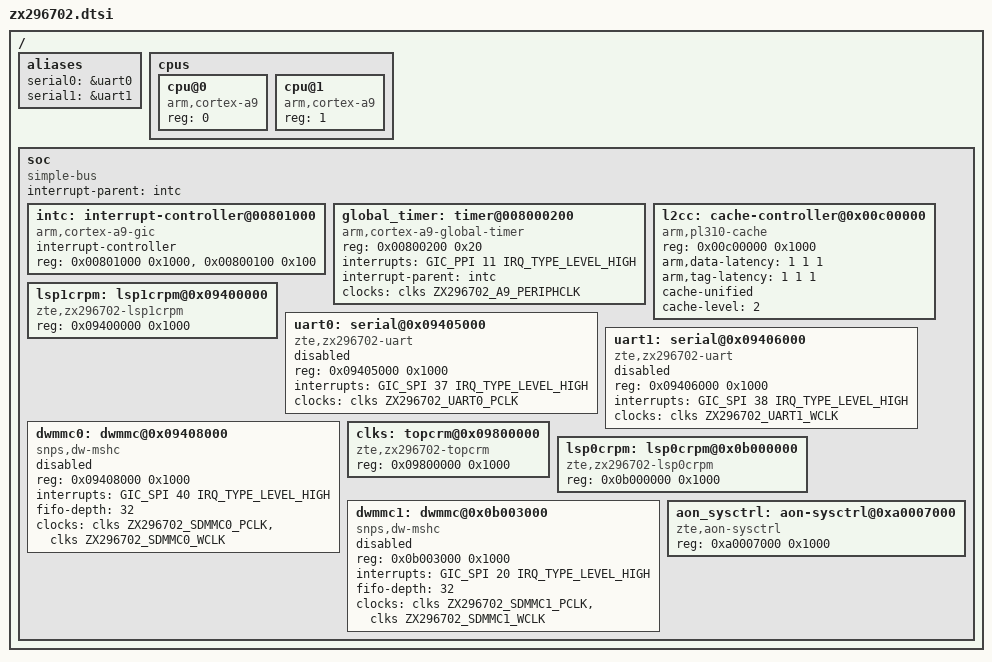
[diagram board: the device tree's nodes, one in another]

#include "skeleton.dtsi"
#include <dt-bindings/clock/zx296702-clock.h>
#include <dt-bindings/interrupt-controller/arm-gic.h>

/ {
	aliases {
		serial0 = &uart0;
		serial1 = &uart1;
	};

	cpus {
		#address-cells = <1>;
		#size-cells = <0>;

		cpu@0 {
			compatible = "arm,cortex-a9";
			device_type = "cpu";
			reg = <0>;
		};

		cpu@1 {
			compatible = "arm,cortex-a9";
			device_type = "cpu";
			reg = <1>;
		};
	};


	soc {
		#address-cells = <1>;
		#size-cells = <1>;
		compatible = "simple-bus";
		interrupt-parent = <&intc>;
		ranges;

		intc: interrupt-controller@00801000 {
			compatible = "arm,cortex-a9-gic";
			#interrupt-cells = <3>;
			#address-cells = <1>;
			#size-cells = <1>;
			interrupt-controller;
			reg = <0x00801000 0x1000>,
			      <0x00800100 0x100>;
		};

		global_timer: timer@008000200 {
			compatible = "arm,cortex-a9-global-timer";
			reg = <0x00800200 0x20>;
			interrupts = <GIC_PPI 11 IRQ_TYPE_LEVEL_HIGH>;
			interrupt-parent = <&intc>;
			clocks = <&clks ZX296702_A9_PERIPHCLK>;
		};

		l2cc: cache-controller@0x00c00000 {
			compatible = "arm,pl310-cache";
			reg = <0x00c00000 0x1000>;
			arm,data-latency = <1 1 1>;
			arm,tag-latency = <1 1 1>;
			cache-unified;
			cache-level = <2>;
		};

		lsp1crpm: lsp1crpm@0x09400000 {
			compatible = "zte,zx296702-lsp1crpm";
			reg = <0x09400000 0x1000>;
		};

		uart0: serial@0x09405000 {
			compatible = "zte,zx296702-uart";
			reg = <0x09405000 0x1000>;
			interrupts = <GIC_SPI 37 IRQ_TYPE_LEVEL_HIGH>;
			clocks = <&clks ZX296702_UART0_PCLK>;
			status = "disabled";
		};

		uart1: serial@0x09406000 {
			compatible = "zte,zx296702-uart";
			reg = <0x09406000 0x1000>;
			interrupts = <GIC_SPI 38 IRQ_TYPE_LEVEL_HIGH>;
			clocks = <&clks ZX296702_UART1_WCLK>;
			status = "disabled";
		};

		dwmmc0: dwmmc@0x09408000 {
			compatible = "snps,dw-mshc";
			#address-cells = <1>;
			#size-cells = <0>;
			reg = <0x09408000 0x1000>;
			interrupts = <GIC_SPI 40 IRQ_TYPE_LEVEL_HIGH>;
			fifo-depth = <32>;
			clocks = <&clks ZX296702_SDMMC0_PCLK>,
				 <&clks ZX296702_SDMMC0_WCLK>;
			clock-names = "biu", "ciu";
			status = "disabled";
		};

		clks: topcrm@0x09800000 {
			compatible = "zte,zx296702-topcrm";
			reg = <0x09800000 0x1000>;
			#clock-cells = <1>;
		};

		lsp0crpm: lsp0crpm@0x0b000000 {
			compatible = "zte,zx296702-lsp0crpm";
			reg = <0x0b000000 0x1000>;
		};

		dwmmc1: dwmmc@0x0b003000 {
			compatible = "snps,dw-mshc";
			#address-cells = <1>;
			#size-cells = <0>;
			reg = <0x0b003000 0x1000>;
			interrupts = <GIC_SPI 20 IRQ_TYPE_LEVEL_HIGH>;
			fifo-depth = <32>;
			clocks = <&clks ZX296702_SDMMC1_PCLK>,
				 <&clks ZX296702_SDMMC1_WCLK>;
			clock-names = "biu", "ciu";
			status = "disabled";
		};

		aon_sysctrl: aon-sysctrl@0xa0007000 {
			compatible = "zte,aon-sysctrl";
			reg = <0xa0007000 0x1000>;
		};
	};
};
